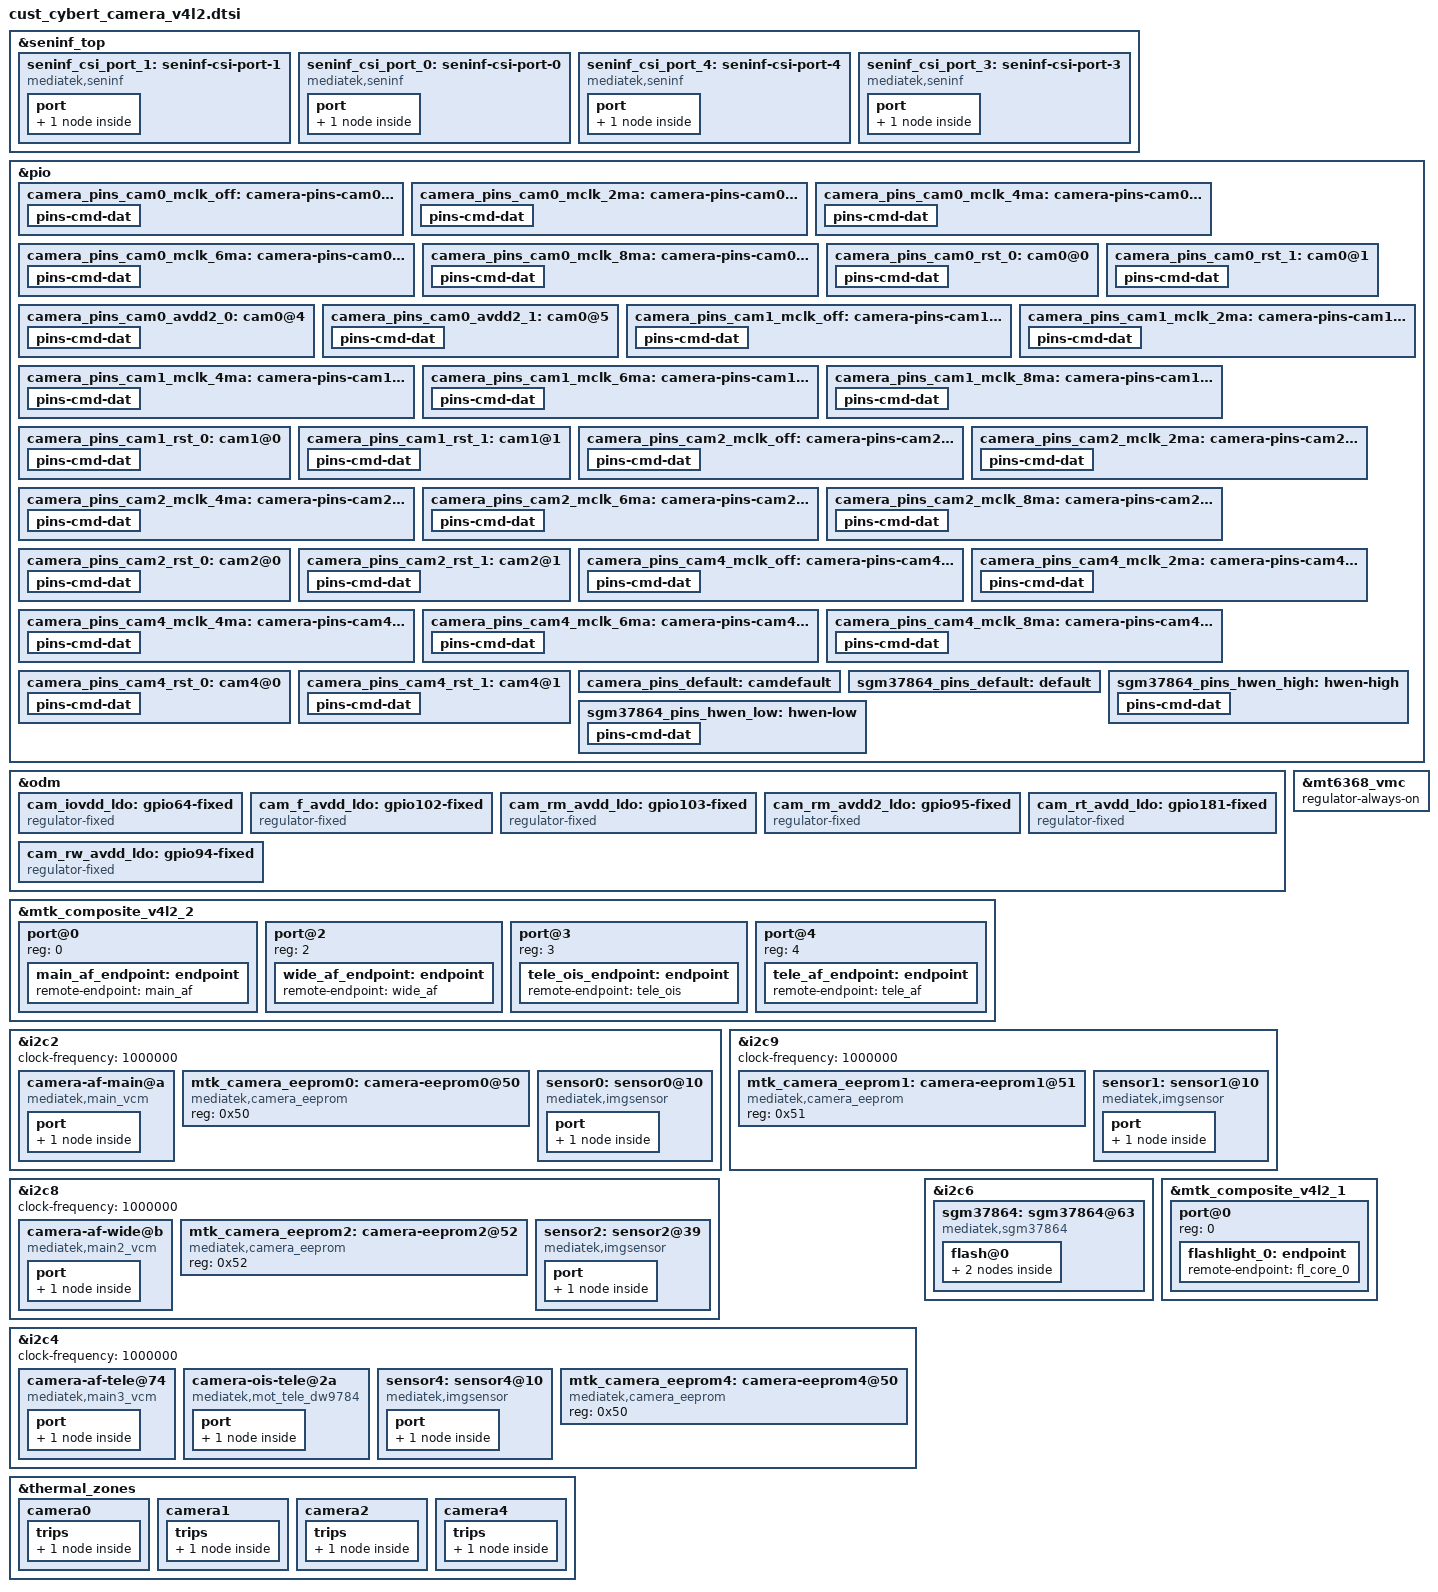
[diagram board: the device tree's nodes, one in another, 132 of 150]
// SPDX-License-Identifier: GPL-2.0
/* Copyright (c) 2020 MediaTek Inc. */
#include <dt-bindings/clock/mt6897-clk.h>
#include <mediatek/cybert_aw37004.dtsi>
#include <mediatek/cybert_aw37004_2nd.dtsi>

&seninf_top {
    seninf_csi_port_1: seninf-csi-port-1 {
        compatible = "mediatek,seninf";
        csi-port = "1";
        hs-trail-parameter = <0x20>;
        nvmem-cells = <&csi_efuse1>;
        nvmem-cell-names = "rg_csi";
        port {
            seninf_csi_port_1_in: endpoint {
                remote-endpoint = <&sensor0_out>;
            };
        };
    };
    seninf_csi_port_0: seninf-csi-port-0 {
        compatible = "mediatek,seninf";
        csi-port = "0";
        dphy-settle-delay-dt = <20>;
        nvmem-cells = <&csi_efuse0>;
        nvmem-cell-names = "rg_csi";
        port {
            seninf_csi_port_0_in: endpoint {
                remote-endpoint = <&sensor1_out>;
            };
        };
    };
    seninf_csi_port_4: seninf-csi-port-4 {
        compatible = "mediatek,seninf";
        csi-port = "4";
        dphy-settle-delay-dt = <17>;
        nvmem-cells = <&csi_efuse4>;
        nvmem-cell-names = "rg_csi";
        port {
            seninf_csi_port_4_in: endpoint {
                remote-endpoint = <&sensor2_out>;
            };
        };
    };
    seninf_csi_port_3: seninf-csi-port-3 {
        compatible = "mediatek,seninf";
        csi-port = "3";
        dphy-settle-delay-dt = <17>;
        nvmem-cells = <&csi_efuse3>;
        nvmem-cell-names = "rg_csi";
        port {
            seninf_csi_port_3_in: endpoint {
                remote-endpoint = <&sensor4_out>;
            };
        };
    };
};


/* CAMERA GPIO fixed to regulator */

&pio {
    camera_pins_cam0_mclk_off: camera-pins-cam0-mclk-off {
        pins-cmd-dat {
            pinmux = <PINMUX_GPIO127__FUNC_GPIO127>;
            drive-strength = <1>;
        };
    };
    camera_pins_cam0_mclk_2ma: camera-pins-cam0-mclk-2ma {
        pins-cmd-dat {
            pinmux = <PINMUX_GPIO127__FUNC_CMMCLK4>;
            drive-strength = <0>;
        };
    };
    camera_pins_cam0_mclk_4ma: camera-pins-cam0-mclk-4ma {
        pins-cmd-dat {
            pinmux = <PINMUX_GPIO127__FUNC_CMMCLK4>;
            drive-strength = <1>;
        };
    };
    camera_pins_cam0_mclk_6ma: camera-pins-cam0-mclk-6ma {
        pins-cmd-dat {
            pinmux = <PINMUX_GPIO127__FUNC_CMMCLK4>;
            drive-strength = <2>;
        };
    };
    camera_pins_cam0_mclk_8ma: camera-pins-cam0-mclk-8ma {
        pins-cmd-dat {
            pinmux = <PINMUX_GPIO127__FUNC_CMMCLK4>;
            drive-strength = <3>;
        };
    };
    camera_pins_cam0_rst_0: cam0@0 {
        pins-cmd-dat {
            pinmux = <PINMUX_GPIO115__FUNC_GPIO115>;
            slew-rate = <1>;
            output-low;
        };
    };
    camera_pins_cam0_rst_1: cam0@1 {
        pins-cmd-dat {
            pinmux = <PINMUX_GPIO115__FUNC_GPIO115>;
            slew-rate = <1>;
            output-high;
        };
    };

    camera_pins_cam0_avdd2_0: cam0@4 {
        pins-cmd-dat {
            pinmux = <PINMUX_GPIO95__FUNC_GPIO95>;
            slew-rate = <1>;
            output-low;
        };
    };
    camera_pins_cam0_avdd2_1: cam0@5 {
        pins-cmd-dat {
            pinmux = <PINMUX_GPIO95__FUNC_GPIO95>;
            slew-rate = <1>;
            output-high;
        };
    };

    camera_pins_cam1_mclk_off: camera-pins-cam1-mclk-off {
        pins-cmd-dat {
            pinmux = <PINMUX_GPIO126__FUNC_GPIO126>;
            drive-strength = <1>;
        };
    };
    camera_pins_cam1_mclk_2ma: camera-pins-cam1-mclk-2ma {
        pins-cmd-dat {
            pinmux = <PINMUX_GPIO126__FUNC_CMMCLK3>;
            drive-strength = <0>;
        };
    };
    camera_pins_cam1_mclk_4ma: camera-pins-cam1-mclk-4ma {
        pins-cmd-dat {
            pinmux = <PINMUX_GPIO126__FUNC_CMMCLK3>;
            drive-strength = <1>;
        };
    };
    camera_pins_cam1_mclk_6ma: camera-pins-cam1-mclk-6ma {
        pins-cmd-dat {
            pinmux = <PINMUX_GPIO126__FUNC_CMMCLK3>;
            drive-strength = <2>;
        };
    };
    camera_pins_cam1_mclk_8ma: camera-pins-cam1-mclk-8ma {
        pins-cmd-dat {
            pinmux = <PINMUX_GPIO126__FUNC_CMMCLK3>;
            drive-strength = <3>;
        };
    };
    camera_pins_cam1_rst_0: cam1@0 {
        pins-cmd-dat {
            pinmux = <PINMUX_GPIO118__FUNC_GPIO118>;
            slew-rate = <1>;
            output-low;
        };
    };
    camera_pins_cam1_rst_1: cam1@1 {
        pins-cmd-dat {
            pinmux = <PINMUX_GPIO118__FUNC_GPIO118>;
            slew-rate = <1>;
            output-high;
        };
    };
    camera_pins_cam2_mclk_off: camera-pins-cam2-mclk-off {
        pins-cmd-dat {
            pinmux = <PINMUX_GPIO125__FUNC_GPIO125>;
            drive-strength = <1>;
        };
    };
    camera_pins_cam2_mclk_2ma: camera-pins-cam2-mclk-2ma {
        pins-cmd-dat {
            pinmux = <PINMUX_GPIO125__FUNC_CMMCLK2>;
            drive-strength = <0>;
        };
    };
    camera_pins_cam2_mclk_4ma: camera-pins-cam2-mclk-4ma {
        pins-cmd-dat {
            pinmux = <PINMUX_GPIO125__FUNC_CMMCLK2>;
            drive-strength = <1>;
        };
    };
    camera_pins_cam2_mclk_6ma: camera-pins-cam2-mclk-6ma {
        pins-cmd-dat {
            pinmux = <PINMUX_GPIO125__FUNC_CMMCLK2>;
            drive-strength = <2>;
        };
    };
    camera_pins_cam2_mclk_8ma: camera-pins-cam2-mclk-8ma {
        pins-cmd-dat {
            pinmux = <PINMUX_GPIO125__FUNC_CMMCLK2>;
            drive-strength = <3>;
        };
    };
    camera_pins_cam2_rst_0: cam2@0 {
        pins-cmd-dat {
            pinmux = <PINMUX_GPIO117__FUNC_GPIO117>;
            slew-rate = <1>;
            output-low;
        };
    };
    camera_pins_cam2_rst_1: cam2@1 {
        pins-cmd-dat {
            pinmux = <PINMUX_GPIO117__FUNC_GPIO117>;
            slew-rate = <1>;
            output-high;
        };
    };
    camera_pins_cam4_mclk_off: camera-pins-cam4-mclk-off {
        pins-cmd-dat {
            pinmux = <PINMUX_GPIO124__FUNC_GPIO124>;
            drive-strength = <1>;
        };
    };
    camera_pins_cam4_mclk_2ma: camera-pins-cam4-mclk-2ma {
        pins-cmd-dat {
            pinmux = <PINMUX_GPIO124__FUNC_CMMCLK1>;
            drive-strength = <0>;
        };
    };
    camera_pins_cam4_mclk_4ma: camera-pins-cam4-mclk-4ma {
        pins-cmd-dat {
            pinmux = <PINMUX_GPIO124__FUNC_CMMCLK1>;
            drive-strength = <1>;
        };
    };
    camera_pins_cam4_mclk_6ma: camera-pins-cam4-mclk-6ma {
        pins-cmd-dat {
            pinmux = <PINMUX_GPIO124__FUNC_CMMCLK1>;
            drive-strength = <2>;
        };
    };
    camera_pins_cam4_mclk_8ma: camera-pins-cam4-mclk-8ma {
        pins-cmd-dat {
            pinmux = <PINMUX_GPIO124__FUNC_CMMCLK1>;
            drive-strength = <3>;
        };
    };
    camera_pins_cam4_rst_0: cam4@0 {
        pins-cmd-dat {
            pinmux = <PINMUX_GPIO116__FUNC_GPIO116>;
            slew-rate = <1>;
            output-low;
        };
    };
    camera_pins_cam4_rst_1: cam4@1 {
        pins-cmd-dat {
            pinmux = <PINMUX_GPIO116__FUNC_GPIO116>;
            slew-rate = <1>;
            output-high;
        };
    };
    camera_pins_default: camdefault {
    };
};
/* CAMERA GPIO end */

&odm {

    cam_iovdd_ldo: gpio64-fixed {
        compatible = "regulator-fixed";
        regulator-name = "cam_iovdd_ldo";
        regulator-min-microvolt = <1800000>;
        regulator-max-microvolt = <1800000>;
        enable-active-high;
        gpio = <&pio 64 0x0>;

    };
    cam_f_avdd_ldo: gpio102-fixed {
        compatible = "regulator-fixed";
        regulator-name = "cam_f_avdd_ldo";
        regulator-min-microvolt = <2800000>;
        regulator-max-microvolt = <2800000>;
        enable-active-high;
        gpio = <&pio 102 0x0>;

    };
/*
    cam_rm_dvdd_ldo: gpio182-fixed {
        compatible = "regulator-fixed";
        regulator-name = "cam_rm_dvdd_ldo";
        regulator-min-microvolt = <1100000>;
        regulator-max-microvolt = <1100000>;
        enable-active-high;
        gpio = <&pio 182 0x0>;

    };
*/
    cam_rm_avdd_ldo: gpio103-fixed {
        compatible = "regulator-fixed";
        regulator-name = "cam_rm_avdd_ldo";
        regulator-min-microvolt = <1800000>;
        regulator-max-microvolt = <1800000>;
        enable-active-high;
        gpio = <&pio 103 0x0>;

    };

    cam_rm_avdd2_ldo: gpio95-fixed {
        compatible = "regulator-fixed";
        regulator-name = "cam_rm_avdd2_ldo";
        regulator-min-microvolt = <2800000>;
        regulator-max-microvolt = <2800000>;
        enable-active-high;
        gpio = <&pio 95 0x0>;

    };


     cam_rt_avdd_ldo: gpio181-fixed {
        compatible = "regulator-fixed";
        regulator-name = "cam_rt_avdd_ldo";
        regulator-min-microvolt = <2800000>;
        regulator-max-microvolt = <2800000>;
        enable-active-high;
        gpio = <&pio 181 0x0>;

    };

     cam_rw_avdd_ldo: gpio94-fixed {
        compatible = "regulator-fixed";
        regulator-name = "cam_rw_avdd_ldo";
        regulator-min-microvolt = <2800000>;
        regulator-max-microvolt = <2800000>;
        enable-active-high;
        gpio = <&pio 94 0x0>;

    };
};

&mtk_composite_v4l2_2 {
    #address-cells = <1>;
    #size-cells = <0>;
    port@0 {
        reg = <0>;
        main_af_endpoint: endpoint {
            remote-endpoint = <&main_af>;
        };
    };

    port@2 {
        reg = <2>;
        wide_af_endpoint: endpoint {
            remote-endpoint = <&wide_af>;
        };
    };

    port@3 {
        reg = <3>;
        tele_ois_endpoint: endpoint {
            remote-endpoint = <&tele_ois>;
        };
    };

    port@4 {
        reg = <4>;
        tele_af_endpoint: endpoint {
            remote-endpoint = <&tele_af>;
        };
    };
};

&i2c2 {
    status = "okay";
    clock-frequency = <1000000>;

    camera-af-main@a {
        compatible = "mediatek,main_vcm";
        reg = <0x0a>;
        vin-supply = <&cam_rm_afvdd_ldo>;
        port {
            main_af: endpoint {
                remote-endpoint = <&main_af_endpoint>;
            };
        };
    };

    mtk_camera_eeprom0:camera-eeprom0@50 {
        compatible = "mediatek,camera_eeprom";
        reg = <0x50>;
        status = "okay";
    };
    sensor0: sensor0@10 {
        compatible = "mediatek,imgsensor";
        sensor-names = "mot_cybert_imx896_mipi_raw";
        reg = <0x10>;

        #thermal-sensor-cells = <0>;

        pinctrl-names = "mclk_off",
                "mclk_2mA",
                "mclk_4mA",
                "mclk_6mA",
                "mclk_8mA",
                "rst_low",
                "rst_high";
        pinctrl-0 = <&camera_pins_cam0_mclk_off>;
        pinctrl-1 = <&camera_pins_cam0_mclk_2ma>;
        pinctrl-2 = <&camera_pins_cam0_mclk_4ma>;
        pinctrl-3 = <&camera_pins_cam0_mclk_6ma>;
        pinctrl-4 = <&camera_pins_cam0_mclk_8ma>;
        pinctrl-5 = <&camera_pins_cam0_rst_0>;
        pinctrl-6 = <&camera_pins_cam0_rst_1>;

        dvdd-supply = <&cam_rm_dvdd_ldo>;
        avdd-supply = <&cam_rm_avdd_ldo>;
        avdd2-supply = <&cam_rm_avdd2_ldo>;
        afvdd-supply = <&cam_rm_afvdd_ldo>;
        dovdd-supply = <&cam_iovdd_ldo>;

        clocks = <&topckgen_clk CLK_TOP_UNIVPLL_192M_D32>,
            <&topckgen_clk CLK_TOP_UNIVPLL_192M_D16>,
            <&topckgen_clk CLK_TOP_F26M_CK_D2>,
            <&topckgen_clk CLK_TOP_UNIVPLL_192M_D10>,
            <&topckgen_clk CLK_TOP_UNIVPLL_192M_D8>,
            <&topckgen_clk CLK_TOP_UNIVPLL_D6_D16>,
            <&topckgen_clk CLK_TOP_UNIVPLL_D6_D8>,
            <&topckgen_clk CLK_TOP_CAMTG5_SEL>;
        clock-names = "6", "12", "13", "19.2", "24", "26", "52", "mclk";


        status = "okay";
        port {
            sensor0_out: endpoint {
                remote-endpoint = <&seninf_csi_port_1_in>;
            };
        };
    };

};

&i2c9 {
    status = "okay";
    clock-frequency = <1000000>;

    mtk_camera_eeprom1:camera-eeprom1@51 {
        compatible = "mediatek,camera_eeprom";
        reg = <0x51>;
        status = "okay";
    };

    sensor1: sensor1@10 {
        compatible = "mediatek,imgsensor";
        sensor-names = "mot_cybert_s5kjns_mipi_raw", "mot_cybert_gc32e1_mipi_raw";
        reg = <0x10>;

        #thermal-sensor-cells = <0>;

        pinctrl-names = "mclk_off",
                "mclk_2mA",
                "mclk_4mA",
                "mclk_6mA",
                "mclk_8mA",
                "rst_low",
                "rst_high";
        pinctrl-0 = <&camera_pins_cam1_mclk_off>;
        pinctrl-1 = <&camera_pins_cam1_mclk_2ma>;
        pinctrl-2 = <&camera_pins_cam1_mclk_4ma>;
        pinctrl-3 = <&camera_pins_cam1_mclk_6ma>;
        pinctrl-4 = <&camera_pins_cam1_mclk_8ma>;
        pinctrl-5 = <&camera_pins_cam1_rst_0>;
        pinctrl-6 = <&camera_pins_cam1_rst_1>;
        dvdd-supply = <&cam_f_dvdd_ldo>;
        avdd-supply = <&cam_f_avdd_ldo>;
        dovdd-supply = <&cam_iovdd_ldo>;

        clocks = <&topckgen_clk CLK_TOP_UNIVPLL_192M_D32>,
            <&topckgen_clk CLK_TOP_UNIVPLL_192M_D16>,
            <&topckgen_clk CLK_TOP_F26M_CK_D2>,
            <&topckgen_clk CLK_TOP_UNIVPLL_192M_D10>,
            <&topckgen_clk CLK_TOP_UNIVPLL_192M_D8>,
            <&topckgen_clk CLK_TOP_UNIVPLL_D6_D16>,
            <&topckgen_clk CLK_TOP_UNIVPLL_D6_D8>,
            <&topckgen_clk CLK_TOP_CAMTG4_SEL>;
        clock-names = "6", "12", "13", "19.2", "24", "26", "52", "mclk";

        status = "okay";
        port {
            sensor1_out: endpoint {
                remote-endpoint = <&seninf_csi_port_0_in>;
            };
        };
    };
};

&i2c8 {
    status = "okay";
    clock-frequency = <1000000>;

    camera-af-wide@b {
        compatible = "mediatek,main2_vcm";
        reg = <0x0b>;
        vin-supply = <&cam_rw_afvdd_ldo>;
        port {
            wide_af: endpoint {
                remote-endpoint = <&wide_af_endpoint>;
            };
        };
    };

    mtk_camera_eeprom2:camera-eeprom2@52 {
        compatible = "mediatek,camera_eeprom";
        reg = <0x52>;
        status = "okay";
    };

    sensor2: sensor2@39 {
        compatible = "mediatek,imgsensor";
        sensor-names = "mot_cybert_s5kjns_uw_mipi_raw";
        reg = <0x39>;

        #thermal-sensor-cells = <0>;

        pinctrl-names = "mclk_off",
                "mclk_2mA",
                "mclk_4mA",
                "mclk_6mA",
                "mclk_8mA",
                "rst_low",
                "rst_high";
        pinctrl-0 = <&camera_pins_cam2_mclk_off>;
        pinctrl-1 = <&camera_pins_cam2_mclk_2ma>;
        pinctrl-2 = <&camera_pins_cam2_mclk_4ma>;
        pinctrl-3 = <&camera_pins_cam2_mclk_6ma>;
        pinctrl-4 = <&camera_pins_cam2_mclk_8ma>;
        pinctrl-5 = <&camera_pins_cam2_rst_0>;
        pinctrl-6 = <&camera_pins_cam2_rst_1>;

        avdd-supply = <&cam_rw_avdd_ldo>;
        dvdd-supply = <&cam_rw_dvdd_ldo>;
        dovdd-supply = <&cam_iovdd_ldo>;

        clocks = <&topckgen_clk CLK_TOP_UNIVPLL_192M_D32>,
            <&topckgen_clk CLK_TOP_UNIVPLL_192M_D16>,
            <&topckgen_clk CLK_TOP_F26M_CK_D2>,
            <&topckgen_clk CLK_TOP_UNIVPLL_192M_D10>,
            <&topckgen_clk CLK_TOP_UNIVPLL_192M_D8>,
            <&topckgen_clk CLK_TOP_UNIVPLL_D6_D16>,
            <&topckgen_clk CLK_TOP_UNIVPLL_D6_D8>,
            <&topckgen_clk CLK_TOP_CAMTG3_SEL>;
        clock-names = "6", "12", "13", "19.2", "24", "26", "52", "mclk";

        status = "okay";
        port {
            sensor2_out: endpoint {
                remote-endpoint = <&seninf_csi_port_4_in>;
            };
        };
    };
};

&i2c4 {
    status = "okay";
    clock-frequency = <1000000>;


    camera-af-tele@74 {
        compatible = "mediatek,main3_vcm";
        reg = <0x74>;
        vin-supply = <&cam_rt_afvdd_ldo>;
        port {
            tele_af: endpoint {
                remote-endpoint = <&tele_af_endpoint>;
            };
        };
    };

    camera-ois-tele@2a {
        compatible = "mediatek,mot_tele_dw9784";
        reg = <0x2a>;
        vdd-supply = <&cam_rt_afvdd_ldo>;
        vin-supply = <&cam_rt_oisvdd_ldo>;
        rst-supply = <&cam_iovdd_ldo>;

        status = "okay";
        port {
            tele_ois: endpoint {
                remote-endpoint = <&tele_ois_endpoint>;
            };
        };
    };

    sensor4: sensor4@10 {
        compatible = "mediatek,imgsensor";
        sensor-names = "mot_cybert_s5k3k1_mipi_raw";
        reg = <0x10>;

        #thermal-sensor-cells = <0>;

        pinctrl-names = "mclk_off",
                "mclk_2mA",
                "mclk_4mA",
                "mclk_6mA",
                "mclk_8mA",
                "rst_low",
                "rst_high";
        pinctrl-0 = <&camera_pins_cam4_mclk_off>;
        pinctrl-1 = <&camera_pins_cam4_mclk_2ma>;
        pinctrl-2 = <&camera_pins_cam4_mclk_4ma>;
        pinctrl-3 = <&camera_pins_cam4_mclk_6ma>;
        pinctrl-4 = <&camera_pins_cam4_mclk_8ma>;
        pinctrl-5 = <&camera_pins_cam4_rst_0>;
        pinctrl-6 = <&camera_pins_cam4_rst_1>;
        avdd-supply = <&cam_rt_avdd_ldo>;
        dvdd-supply = <&cam_rt_dvdd_ldo>;
        dovdd-supply = <&cam_iovdd_ldo>;

        clocks = <&topckgen_clk CLK_TOP_UNIVPLL_192M_D32>,
            <&topckgen_clk CLK_TOP_UNIVPLL_192M_D16>,
            <&topckgen_clk CLK_TOP_F26M_CK_D2>,
            <&topckgen_clk CLK_TOP_UNIVPLL_192M_D10>,
            <&topckgen_clk CLK_TOP_UNIVPLL_192M_D8>,
            <&topckgen_clk CLK_TOP_UNIVPLL_D6_D16>,
            <&topckgen_clk CLK_TOP_UNIVPLL_D6_D8>,
            <&topckgen_clk CLK_TOP_CAMTG2_SEL>;
        clock-names = "6", "12", "13", "19.2", "24", "26", "52", "mclk";

        status = "okay";
        port {
            sensor4_out: endpoint {
                remote-endpoint = <&seninf_csi_port_3_in>;
            };
        };
    };

    mtk_camera_eeprom4:camera-eeprom4@50 {
        compatible = "mediatek,camera_eeprom";
        reg = <0x50>;
        status = "okay";
    };
};

&thermal_zones {
    camera0: camera0 {
        polling-delay = <0>; /* milliseconds */
        polling-delay-passive = <0>; /* milliseconds */
        thermal-sensors = <&sensor0>;
        trips {
            camera0_crit: camera0-crit {
                temperature = <120000>;
                hysteresis = <2000>;
                type = "passive";
            };
        };
    };
    camera1: camera1 {
        polling-delay = <0>; /* milliseconds */
        polling-delay-passive = <0>; /* milliseconds */
        thermal-sensors = <&sensor1>;
        trips {
            camera1_crit: camera1-crit {
                temperature = <120000>;
                hysteresis = <2000>;
                type = "passive";
            };
        };
    };
    camera2: camera2 {
        polling-delay = <0>; /* milliseconds */
        polling-delay-passive = <0>; /* milliseconds */
        thermal-sensors = <&sensor2>;
        trips {
            camera2_crit: camera2-crit {
                temperature = <120000>;
                hysteresis = <2000>;
                type = "passive";
            };
        };
    };
    camera4: camera4 {
        polling-delay = <0>; /* milliseconds */
        polling-delay-passive = <0>; /* milliseconds */
        thermal-sensors = <&sensor4>;
        trips {
            camera4_crit: camera4-crit {
                temperature = <120000>;
                hysteresis = <2000>;
                type = "passive";
            };
        };
    };

};

&mt6368_vmc {
    regulator-always-on;
};

&i2c6 {
    #address-cells = <1>;
    #size-cells = <0>;
    sgm37864:sgm37864@63 {
        compatible = "mediatek,sgm37864";
        #address-cells = <1>;
        #size-cells = <0>;
        reg = <0x63>;
        #cooling-cells = <2>;
        pinctrl-names = "default", "hwen-high", "hwen-low";
        pinctrl-0 = <&sgm37864_pins_default>;
        pinctrl-1 = <&sgm37864_pins_hwen_high>;
        pinctrl-2 = <&sgm37864_pins_hwen_low>;
        status = "okay";
        flash@0{
            reg = <0>;
            type = <0>;
            ct = <0>;
            part = <0>;
            port {
                fl_core_0: endpoint {
                    remote-endpoint = <&flashlight_0>;
                };
            };
        };
    };
};



&pio {
    sgm37864_pins_default: default {
    };

    sgm37864_pins_hwen_high: hwen-high {
        pins-cmd-dat {
            pinmux = <PINMUX_GPIO73__FUNC_GPIO73>;
            slew-rate = <1>;
            output-high;
        };
    };

    sgm37864_pins_hwen_low: hwen-low {
        pins-cmd-dat {
            pinmux = <PINMUX_GPIO73__FUNC_GPIO73>;
            slew-rate = <1>;
            output-low;
        };
    };
};


&mtk_composite_v4l2_1 {
    #address-cells = <1>;
    #size-cells = <0>;
    port@0 {
        reg = <0>;
        flashlight_0: endpoint {
            remote-endpoint = <&fl_core_0>;
        };
    };
};
